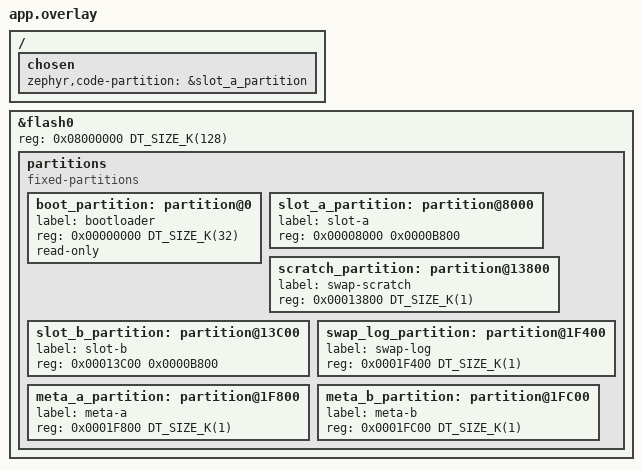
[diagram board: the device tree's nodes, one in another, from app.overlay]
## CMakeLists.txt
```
cmake_minimum_required(VERSION 3.20.0)

find_package(Zephyr REQUIRED HINTS $ENV{ZEPHYR_BASE})
project(f103_application_template)

target_sources(app PRIVATE
  src/main.c
  src/runtime_usb.c
  ../src/flash_update.c
  ../common/f103_bootloader_api.c
)

target_include_directories(app PRIVATE
  include
  ../include
  ../src
  ../common
)
```

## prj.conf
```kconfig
CONFIG_LOG=y
CONFIG_LOG_MODE_IMMEDIATE=y
CONFIG_LOG_DEFAULT_LEVEL=3
CONFIG_CONSOLE=y
CONFIG_SERIAL=y
CONFIG_UART_CONSOLE=y
CONFIG_USE_DT_CODE_PARTITION=y

# The application writes the image_ok confirmation into the metadata page.
CONFIG_FLASH=y
CONFIG_FLASH_PAGE_LAYOUT=y
CONFIG_CRC=y

CONFIG_MAIN_STACK_SIZE=2048
CONFIG_SYSTEM_WORKQUEUE_STACK_SIZE=2048

CONFIG_USB_DEVICE_STACK=y
CONFIG_USB_DEVICE_STACK_NEXT=n
CONFIG_USB_DEVICE_HID=y
CONFIG_ENABLE_HID_INT_OUT_EP=y
CONFIG_HID_INTERRUPT_EP_MPS=64
CONFIG_USB_HID_POLL_INTERVAL_MS=1
CONFIG_USB_DEVICE_VID=0x1209
CONFIG_USB_DEVICE_PID=0xF103
CONFIG_USB_DEVICE_MANUFACTURER="F103 Open Project"
CONFIG_USB_DEVICE_PRODUCT="F103 USB Application"
CONFIG_USB_DEVICE_SN="F103-APP-0001"
CONFIG_USB_DC_STM32_CLOCK_CHECK=n
CONFIG_WARN_DEPRECATED=n
```

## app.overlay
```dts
/*
 * Application side of the F103 USB bootloader layout.
 * Single image, linked for slot A (the boot slot). The bootloader
 * downloads into slot B and swaps it into slot A sector by sector.
 */

&flash0 {
	reg = <0x08000000 DT_SIZE_K(128)>;

	partitions {
		compatible = "fixed-partitions";
		#address-cells = <1>;
		#size-cells = <1>;

		boot_partition: partition@0 {
			label = "bootloader";
			reg = <0x00000000 DT_SIZE_K(32)>;
			read-only;
		};

		slot_a_partition: partition@8000 {
			label = "slot-a";
			reg = <0x00008000 0x0000B800>;
		};

		scratch_partition: partition@13800 {
			label = "swap-scratch";
			reg = <0x00013800 DT_SIZE_K(1)>;
		};

		slot_b_partition: partition@13C00 {
			label = "slot-b";
			reg = <0x00013C00 0x0000B800>;
		};

		swap_log_partition: partition@1F400 {
			label = "swap-log";
			reg = <0x0001F400 DT_SIZE_K(1)>;
		};

		meta_a_partition: partition@1F800 {
			label = "meta-a";
			reg = <0x0001F800 DT_SIZE_K(1)>;
		};

		meta_b_partition: partition@1FC00 {
			label = "meta-b";
			reg = <0x0001FC00 DT_SIZE_K(1)>;
		};
	};
};

/ {
	chosen {
		zephyr,code-partition = &slot_a_partition;
	};
};
```

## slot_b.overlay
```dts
/*
 * Application image linked for slot B.
 */

&flash0 {
	reg = <0x08000000 DT_SIZE_K(128)>;

	partitions {
		compatible = "fixed-partitions";
		#address-cells = <1>;
		#size-cells = <1>;

		boot_partition: partition@0 {
			label = "bootloader";
			reg = <0x00000000 DT_SIZE_K(32)>;
			read-only;
		};

		slot_a_partition: partition@8000 {
			label = "slot-a";
			reg = <0x00008000 0x0000BC00>;
		};

		slot_b_partition: partition@13C00 {
			label = "slot-b";
			reg = <0x00013C00 0x0000BC00>;
		};

		meta_a_partition: partition@1F800 {
			label = "meta-a";
			reg = <0x0001F800 DT_SIZE_K(1)>;
		};

		meta_b_partition: partition@1FC00 {
			label = "meta-b";
			reg = <0x0001FC00 DT_SIZE_K(1)>;
		};
	};
};

/ {
	chosen {
		zephyr,code-partition = &slot_b_partition;
	};
};
```

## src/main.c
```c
/*
 * Minimal Zephyr application linked for the F103 USB bootloader.
 *
 * SPDX-License-Identifier: Apache-2.0
 */

#include "app_version.h"
#include "f103_bootloader_api.h"
#include "f103_fw_version.h"
#include "runtime_usb.h"

#include <zephyr/kernel.h>
#include <zephyr/logging/log.h>

LOG_MODULE_REGISTER(app, LOG_LEVEL_INF);

/*
 * Version block parsed by the bootloader (slot A scan) and reported over
 * the PING command. Keep this block at a fixed layout.
 */
__attribute__((used, retain, section(".rodata.fw_version")))
const struct f103_fw_version f103_app_fw_version = {
	.magic = F103_FW_VERSION_MAGIC,
	.major = APP_FW_VERSION_MAJOR,
	.minor = APP_FW_VERSION_MINOR,
	.patch = APP_FW_VERSION_PATCH,
	.build = APP_FW_VERSION_BUILD,
	.reserved = F103_FW_VERSION_RESERVED,
};

int main(void)
{
	LOG_INF("F103 application started");

	if (runtime_usb_init() < 0) {
		LOG_ERR("Runtime USB upgrade interface failed");
	} else if (f103_bootloader_confirm_image()) {
		/* Replace with the real product self-test before confirming. */
		LOG_INF("Self-test passed, image confirmed (image_ok)");
	} else {
		LOG_INF("No pending image to confirm");
	}

	while (true) {
		if (runtime_usb_wait_for_boot_timeout(K_SECONDS(5)) == 0) {
			LOG_INF("Host requested bootloader");
			runtime_usb_restart_to_bootloader();
		}
		LOG_INF("Application alive");
	}
}
```

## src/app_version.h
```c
/*
 * Application firmware version.
 *
 * SPDX-License-Identifier: Apache-2.0
 */

#ifndef APP_VERSION_H_
#define APP_VERSION_H_

#define APP_FW_VERSION_MAJOR 1
#define APP_FW_VERSION_MINOR 0
#define APP_FW_VERSION_PATCH 0
#define APP_FW_VERSION_BUILD 1

#endif /* APP_VERSION_H_ */
```

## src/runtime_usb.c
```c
/*
 * Persistent USB HID service for entering the bootloader without a reset
 * button or a USB replug.
 *
 * SPDX-License-Identifier: Apache-2.0
 */

#include "runtime_usb.h"

#include "app_version.h"
#include "f103_bootloader_api.h"
#include "f103_fw_version.h"
#include "f103_hid_descriptor.h"
#include "f103_iap.h"

#include <stdbool.h>
#include <string.h>

#include <stm32f1xx.h>
#include <zephyr/device.h>
#include <zephyr/kernel.h>
#include <zephyr/sys/byteorder.h>
#include <zephyr/usb/class/usb_hid.h>
#include <zephyr/usb/usb_device.h>

static const struct device *hid_device;

extern const struct f103_fw_version f103_app_fw_version;

#define APP_VERSION_WORD \
	F103_FW_VERSION_WORD(f103_app_fw_version.major, \
			     f103_app_fw_version.minor, \
			     f103_app_fw_version.patch)

static K_SEM_DEFINE(boot_request_sem, 0, 1);

static K_TIMER_DEFINE(boot_request_timer, NULL, NULL);

static void boot_timer_expiry(struct k_timer *timer)
{
	ARG_UNUSED(timer);
	k_sem_give(&boot_request_sem);
}

static void send_response(uint8_t command, uint8_t sequence, uint8_t status,
			  uint32_t value, uint8_t role)
{
	uint8_t report[F103_HID_REPORT_SIZE] = {0U};

	report[0] = F103_HID_REPORT_ID_IN;
	report[1] = status;
	report[2] = command;
	report[3] = sequence;
	sys_put_le32(value, &report[4]);
	report[8 + 12] = role;
	sys_put_le32(APP_VERSION_WORD, &report[8 + 24]);
	report[8 + 28] = (uint8_t)f103_app_fw_version.build;
	report[8 + 29] = 1U; /* firmware version valid */

	(void)hid_int_ep_write(hid_device, report, sizeof(report), NULL);
}

static void process_request(const uint8_t *request, size_t length)
{
	uint8_t command;
	uint8_t sequence;
	uint8_t data_length;
	uint8_t status = F103_IAP_OK;
	uint32_t value = 0U;
	bool request_boot = false;

	if (length > 0U && request[0] == F103_HID_REPORT_ID_OUT) {
		request++;
		length--;
	}

	if (length < F103_IAP_HEADER_SIZE ||
	    request[0] != F103_IAP_MAGIC0 ||
	    request[1] != F103_IAP_MAGIC1) {
		return;
	}

	command = request[2];
	sequence = request[3];
	data_length = request[8];

	if (data_length > F103_HID_DATA_MAX ||
	    (size_t)data_length > length - F103_IAP_HEADER_SIZE) {
		status = F103_IAP_ERR_ARG;
	} else if (command == F103_IAP_PING) {
		value = F103_IAP_VERSION;
	} else if (command == F103_IAP_ENTER_BOOTLOADER) {
		request_boot = true;
	} else {
		status = F103_IAP_ERR_COMMAND;
	}

	send_response(command, sequence, status, value, F103_IAP_ROLE_APPLICATION);
	if (request_boot) {
		/*
		 * Give the IN transfer time to complete before main() powers
		 * down USB and resets the MCU.
		 */
		k_timer_start(&boot_request_timer, K_MSEC(50), K_NO_WAIT);
	}
}

static void hid_int_out_ready_cb(const struct device *dev)
{
	uint8_t report[F103_HID_REPORT_SIZE];
	uint32_t received = 0U;

	if (hid_int_ep_read(dev, report, sizeof(report), &received) == 0 &&
	    received > 0U) {
		process_request(report, received);
	}
}

static const struct hid_ops hid_ops = {
	.int_out_ready = hid_int_out_ready_cb,
};

static void usb_status_cb(enum usb_dc_status_code status, const uint8_t *param)
{
	ARG_UNUSED(status);
	ARG_UNUSED(param);
}

static void usb_disconnect_dp(void)
{
	RCC->APB2ENR |= RCC_APB2ENR_IOPAEN;
	(void)RCC->APB2ENR;

	GPIOA->CRH = (GPIOA->CRH & ~(0xFU << 16)) | (0x2U << 16);
	GPIOA->BSRR = GPIO_BSRR_BR12;
	__DSB();
}

int runtime_usb_init(void)
{
	hid_device = device_get_binding("HID_0");
	if (hid_device == NULL) {
		return -ENODEV;
	}

	usb_hid_register_device(hid_device, f103_hid_report_descriptor,
				sizeof(f103_hid_report_descriptor), &hid_ops);
	usb_hid_init(hid_device);

	k_timer_init(&boot_request_timer, boot_timer_expiry, NULL);
	return usb_enable(usb_status_cb);
}

int runtime_usb_wait_for_boot_timeout(k_timeout_t timeout)
{
	return k_sem_take(&boot_request_sem, timeout);
}

void runtime_usb_restart_to_bootloader(void)
{
	(void)usb_disable();
	k_sleep(K_MSEC(100));

	usb_disconnect_dp();
	f103_bootloader_mark_request();

	/* Leave D+ low long enough for the host to detect a disconnect. */
	k_sleep(K_MSEC(200));
	NVIC_SystemReset();

	__builtin_unreachable();
}
```

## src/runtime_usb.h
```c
/*
 * Runtime USB upgrade interface.
 *
 * SPDX-License-Identifier: Apache-2.0
 */

#ifndef RUNTIME_USB_H_
#define RUNTIME_USB_H_

#include <zephyr/kernel.h>

int runtime_usb_init(void);

/* Wait until the host requests a transition into the bootloader. */
int runtime_usb_wait_for_boot_timeout(k_timeout_t timeout);

/* Disconnect D+, persist the request and reset into the bootloader. */
void runtime_usb_restart_to_bootloader(void) __attribute__((noreturn));

#endif /* RUNTIME_USB_H_ */
```
